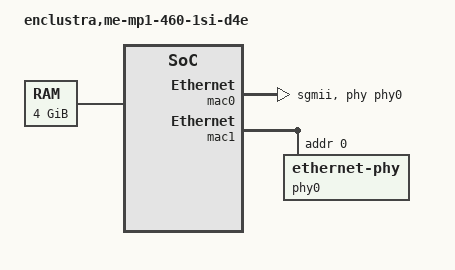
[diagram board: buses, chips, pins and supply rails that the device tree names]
// SPDX-License-Identifier: (GPL-2.0+ OR MIT)
/*
 * Copyright (C) 2022 Enclustra GmbH
 * <info@enclustra.com>
 */

/dts-v1/;

#include "enclustra_mercury_mp1_common.dtsi"

/ {
	model = "enclustra,me-mp1-460-1si-d4e";

	aliases {
		ethernet0 = &mac0;
		ethernet1 = &mac1;
	};

	/* 4 Gbyte DDR4 memory */
	mss_memory: memory@1000000000 {
		device_type = "memory";
		reg = <0x10 0x0 0x1 0x0>;
		status = "okay";
	};
};

&mac0 {
	status = "okay";
	/delete-property/ mac-address;
	/delete-property/ local-mac-address;
	phy-mode = "sgmii";
	phy-handle = <&phy0>;
};

&mac1 {
	phy0: ethernet-phy@0 {
		reg = <0>;
	};
};
